AUTOSAR XML (schema 00049)
package /SwComponentTypes
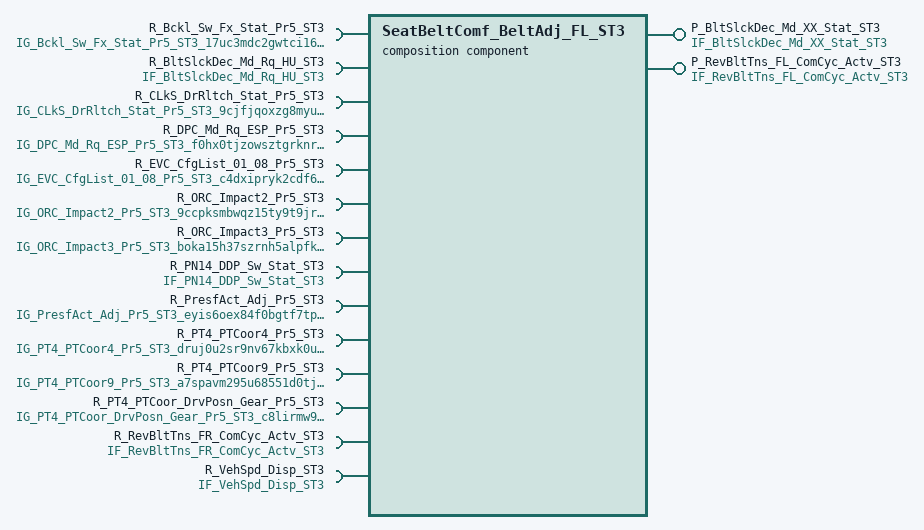
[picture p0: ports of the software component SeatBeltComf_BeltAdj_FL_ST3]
  composition sw component type SeatBeltComf_BeltAdj_FL_ST3  # Gurtkomfort Gurtanpassung vorne links / Seat Belt Comfort Belt Adjustment Front Left
    provide port P_BltSlckDec_Md_XX_Stat_ST3: nonqueued-sender-com-spec{data-element=BltSlckDec_Md_XX_Stat_ST3, init-value=constant-reference=XDIS_1vei4uht6zuq0e57z2qtds6y7}, provided-interface=IF_BltSlckDec_Md_XX_Stat_ST3  # Modus Gurtlosereduktion Status / Belt slack decreasing mode state
    provide port P_RevBltTns_FL_ComCyc_Actv_ST3: nonqueued-sender-com-spec{data-element=RevBltTns_FL_ComCyc_Actv_ST3, init-value=constant-reference=XDIS_f4mtuwvd3r353o80f6rps7w7}, provided-interface=IF_RevBltTns_FL_ComCyc_Actv_ST3  # Reversibler Gurtstraffer vorne links Komfort-Straffzyklus aktiv / Reversible belt tensioner front left comfort tensioning cycle active
    14 x require port:
      R_Bckl_Sw_Fx_Stat_Pr5_ST3: nonqueued-receiver-com-spec{data-element=Bckl_Sw_Fx_Stat_Pr5_ST3, reception-props=timeout=1.1, end-to-end-transformation-com-spec-props=disable-end-to-end-check=true, alive-timeout=1.1, init-value=constant-reference=XDIS_1ib0iwqn283njrf47me9zcot}, required-interface=IG_Bckl_Sw_Fx_Stat_Pr5_ST3_17uc3mdc2gwtci163emdxcwq  # Bckl Sw Fx Status ST3 (degraded) / Bckl Sw Fx state ST3 (degraded)
      R_BltSlckDec_Md_Rq_HU_ST3: nonqueued-receiver-com-spec{data-element=BltSlckDec_Md_Rq_HU_ST3, reception-props=timeout=60.5, alive-timeout=60.5, init-value=constant-reference=XDIS_1vei4uht6zuq0e57z2qtds6y7}, required-interface=IF_BltSlckDec_Md_Rq_HU_ST3  # Anforderung Modus Gurtlosereduktion von Headunit / Belt slack decreasing mode request from Head Unit
      R_CLkS_DrRltch_Stat_Pr5_ST3: nonqueued-receiver-com-spec{data-element=CLkS_DrRltch_Stat_Pr5_ST3, reception-props=timeout=0, end-to-end-transformation-com-spec-props=disable-end-to-end-check=true, init-value=constant-reference=XDIS_2cviwteq6sdkb41vg3juq8qm5}, required-interface=IG_CLkS_DrRltch_Stat_Pr5_ST3_9cjfjqoxzg8myue62zdg7b3ws  # Zentralverriegelung Status Drehfalle Türen (degraded) / Central Locking System Rotary latch doors state (degraded)
      R_DPC_Md_Rq_ESP_Pr5_ST3: nonqueued-receiver-com-spec{data-element=DPC_Md_Rq_ESP_Pr5_ST3, reception-props=timeout=0, end-to-end-transformation-com-spec-props=disable-end-to-end-check=true, init-value=constant-reference=XDIS_1k0wiwna366gg0qdmxvrmtw5q}, required-interface=IG_DPC_Md_Rq_ESP_Pr5_ST3_f0hx0tjzowsztgrknro9jwuwh  # Dynamic select Anforderung Pr 5 ST3 (degraded) / Dynamic select request Pr 5 ST3 (degraded)
      R_EVC_CfgList_01_08_Pr5_ST3: nonqueued-receiver-com-spec{data-element=EVC_CfgList_01_08_Pr5_ST3, reception-props=timeout=0, end-to-end-transformation-com-spec-props=disable-end-to-end-check=true, init-value=constant-reference=XDIS_806a649zhaoqji1vpc640aqar}, required-interface=IG_EVC_CfgList_01_08_Pr5_ST3_c4dxipryk2cdf6g3u376iowg4  # EVC Cfg List 01 08 Pr 5 ST3 (degraded)
      R_ORC_Impact2_Pr5_ST3: nonqueued-receiver-com-spec{data-element=ORC_Impact2_Pr5_ST3, reception-props=timeout=0, end-to-end-transformation-com-spec-props=disable-end-to-end-check=true, init-value=constant-reference=XDIS_6l5b88fcuqpu2imoz1fzls07a}, required-interface=IG_ORC_Impact2_Pr5_ST3_9ccpksmbwqz15ty9t9jr7ps1e  # ORC Impact 2 ST3 (degraded)
      R_ORC_Impact3_Pr5_ST3: nonqueued-receiver-com-spec{data-element=ORC_Impact3_Pr5_ST3, reception-props=timeout=0, end-to-end-transformation-com-spec-props=disable-end-to-end-check=true, init-value=constant-reference=XDIS_ayiqyrhz0dpk9ygbqo5e5w1f7}, required-interface=IG_ORC_Impact3_Pr5_ST3_boka15h37szrnh5alpfk2b7or  # ORC Impact 3 ST3 (degraded)
      R_PN14_DDP_Sw_Stat_ST3: nonqueued-receiver-com-spec{data-element=PN14_DDP_Sw_Stat_ST3, reception-props=timeout=0, init-value=constant-reference=XDIS_c8apwmaohcx1gxigvciebloy2}, required-interface=IF_PN14_DDP_Sw_Stat_ST3  # Schalterstatus Tiefentladeschutz / Deep discharge protection switch state
      R_PresfAct_Adj_Pr5_ST3: nonqueued-receiver-com-spec{data-element=PresfAct_Adj_Pr5_ST3, reception-props=timeout=0, end-to-end-transformation-com-spec-props=disable-end-to-end-check=true, init-value=constant-reference=XDIS_8ojfkfkqplxm6o5fjyuoflsu9}, required-interface=IG_PresfAct_Adj_Pr5_ST3_eyis6oex84f0bgtf7tp8d31fv  # Presf Aktor Steuerung ST3 (degraded) / Presf Actuator adjustment ST3 (degraded)
      R_PT4_PTCoor4_Pr5_ST3: nonqueued-receiver-com-spec{data-element=PT4_PTCoor4_Pr5_ST3, reception-props=timeout=1.05, end-to-end-transformation-com-spec-props=disable-end-to-end-check=true, alive-timeout=1.05, init-value=constant-reference=XDIS_6ihabh6lptobki7z27hgr4m4g}, required-interface=IG_PT4_PTCoor4_Pr5_ST3_druj0u2sr9nv67kbxk0u6ab4e  # PT4_PTCoor4_Pr5_ST3 (degraded)
      R_PT4_PTCoor9_Pr5_ST3: nonqueued-receiver-com-spec{data-element=PT4_PTCoor9_Pr5_ST3, reception-props=timeout=5.1, end-to-end-transformation-com-spec-props=disable-end-to-end-check=true, alive-timeout=5.1, init-value=constant-reference=XDIS_4ns7wihv1xzpelli7hay25trg}, required-interface=IG_PT4_PTCoor9_Pr5_ST3_a7spavm295u68551d0tj6tl4v  # PT4 PT Coor 9 Pr 5 ST3 (degraded)
      R_PT4_PTCoor_DrvPosn_Gear_Pr5_ST3: nonqueued-receiver-com-spec{data-element=PT4_PTCoor_DrvPosn_Gear_Pr5_ST3, reception-props=timeout=0, end-to-end-transformation-com-spec-props=disable-end-to-end-check=true, init-value=constant-reference=XDIS_8ocy3iwo1ditemd6qwphg7b7i}, required-interface=IG_PT4_PTCoor_DrvPosn_Gear_Pr5_ST3_c8lirmw9wm5odas0h648yyd4w  # PT4 PT Coor Drv Position Gear Pr 5 ST3 (degraded) / PT4 PT Coor Drv position Gear Pr 5 ST3 (degraded)
      R_RevBltTns_FR_ComCyc_Actv_ST3: nonqueued-receiver-com-spec{data-element=RevBltTns_FR_ComCyc_Actv_ST3, reception-props=timeout=0, init-value=constant-reference=XDIS_f4mtuwvd3r353o80f6rps7w7}, required-interface=IF_RevBltTns_FR_ComCyc_Actv_ST3  # Reversibler Gurtstraffer vorne rechts Komfort-Straffzyklus aktiv / Reversible belt tensioner front right comfort tensioning cycle active
      R_VehSpd_Disp_ST3: nonqueued-receiver-com-spec{data-element=VehSpd_Disp_ST3, reception-props=timeout=10.5, alive-timeout=10.5, init-value=constant-reference=XDIS_5khg03e556s88aodw5p7cozx4}, required-interface=IF_VehSpd_Disp_ST3  # Angezeigte Geschwindigkeit (ohne Zeigerdämpfung) / Displayed vehicle speed (without attenuation)
    component BeltAdjFunction: type=BeltAdjFunction
    delegate BeltAdjFunction.P_RevBltTns_FL_ComCyc_Actv_ST3 <-> outer port P_RevBltTns_FL_ComCyc_Actv_ST3
    delegate BeltAdjFunction.R_DPC_Md_Rq_ESP_Pr5_ST3 <-> outer port R_DPC_Md_Rq_ESP_Pr5_ST3
    delegate BeltAdjFunction.R_PresfAct_Adj_Pr5_ST3 <-> outer port R_PresfAct_Adj_Pr5_ST3
    delegate BeltAdjFunction.R_CLkS_DrRltch_Stat_Pr5_ST3 <-> outer port R_CLkS_DrRltch_Stat_Pr5_ST3
    delegate BeltAdjFunction.R_PT4_PTCoor9_Pr5_ST3 <-> outer port R_PT4_PTCoor9_Pr5_ST3
    delegate BeltAdjFunction.R_RevBltTns_FR_ComCyc_Actv_ST3 <-> outer port R_RevBltTns_FR_ComCyc_Actv_ST3
    delegate BeltAdjFunction.R_Bckl_Sw_Fx_Stat_Pr5_ST3 <-> outer port R_Bckl_Sw_Fx_Stat_Pr5_ST3
    delegate BeltAdjFunction.R_EVC_CfgList_01_08_Pr5_ST3 <-> outer port R_EVC_CfgList_01_08_Pr5_ST3
    delegate BeltAdjFunction.R_ORC_Impact2_Pr5_ST3 <-> outer port R_ORC_Impact2_Pr5_ST3
    delegate BeltAdjFunction.R_ORC_Impact3_Pr5_ST3 <-> outer port R_ORC_Impact3_Pr5_ST3
    delegate BeltAdjFunction.R_PN14_DDP_Sw_Stat_ST3 <-> outer port R_PN14_DDP_Sw_Stat_ST3
    delegate BeltAdjFunction.R_VehSpd_Disp_ST3 <-> outer port R_VehSpd_Disp_ST3
    delegate BeltAdjFunction.R_BltSlckDec_Md_Rq_HU_ST3 <-> outer port R_BltSlckDec_Md_Rq_HU_ST3
    delegate BeltAdjFunction.R_PT4_PTCoor4_Pr5_ST3 <-> outer port R_PT4_PTCoor4_Pr5_ST3
    delegate BeltAdjFunction.R_PT4_PTCoor_DrvPosn_Gear_Pr5_ST3 <-> outer port R_PT4_PTCoor_DrvPosn_Gear_Pr5_ST3
